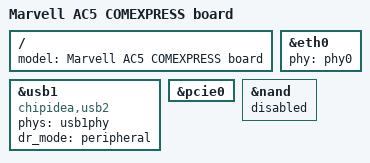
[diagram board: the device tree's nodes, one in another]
// SPDX-License-Identifier: (GPL-2.0+ OR MIT)
/*
 * Device Tree For AC5 comExpress.
 *
 * Copyright (C) 2021 Marvell
 *
 */
// SPDX-License-Identifier: (GPL-2.0+ OR MIT)
/*
 * Device Tree file for Marvell AC5 comExpress development board
 * This board file supports the B configuration of the board
 */

#include "ac5.dtsi"

/ {
	model = "Marvell AC5 COMEXPRESS board";
};

&eth0 {
	status = "okay";
	phy = <&phy0>;
};

&usb1 {
	compatible = "chipidea,usb2";
	phys = <&usb1phy>;
	phy-names = "usb-phy";
	dr_mode = "peripheral";
};

&pcie0 {
	status = "okay";
};

&nand {
	status = "disabled";
};
